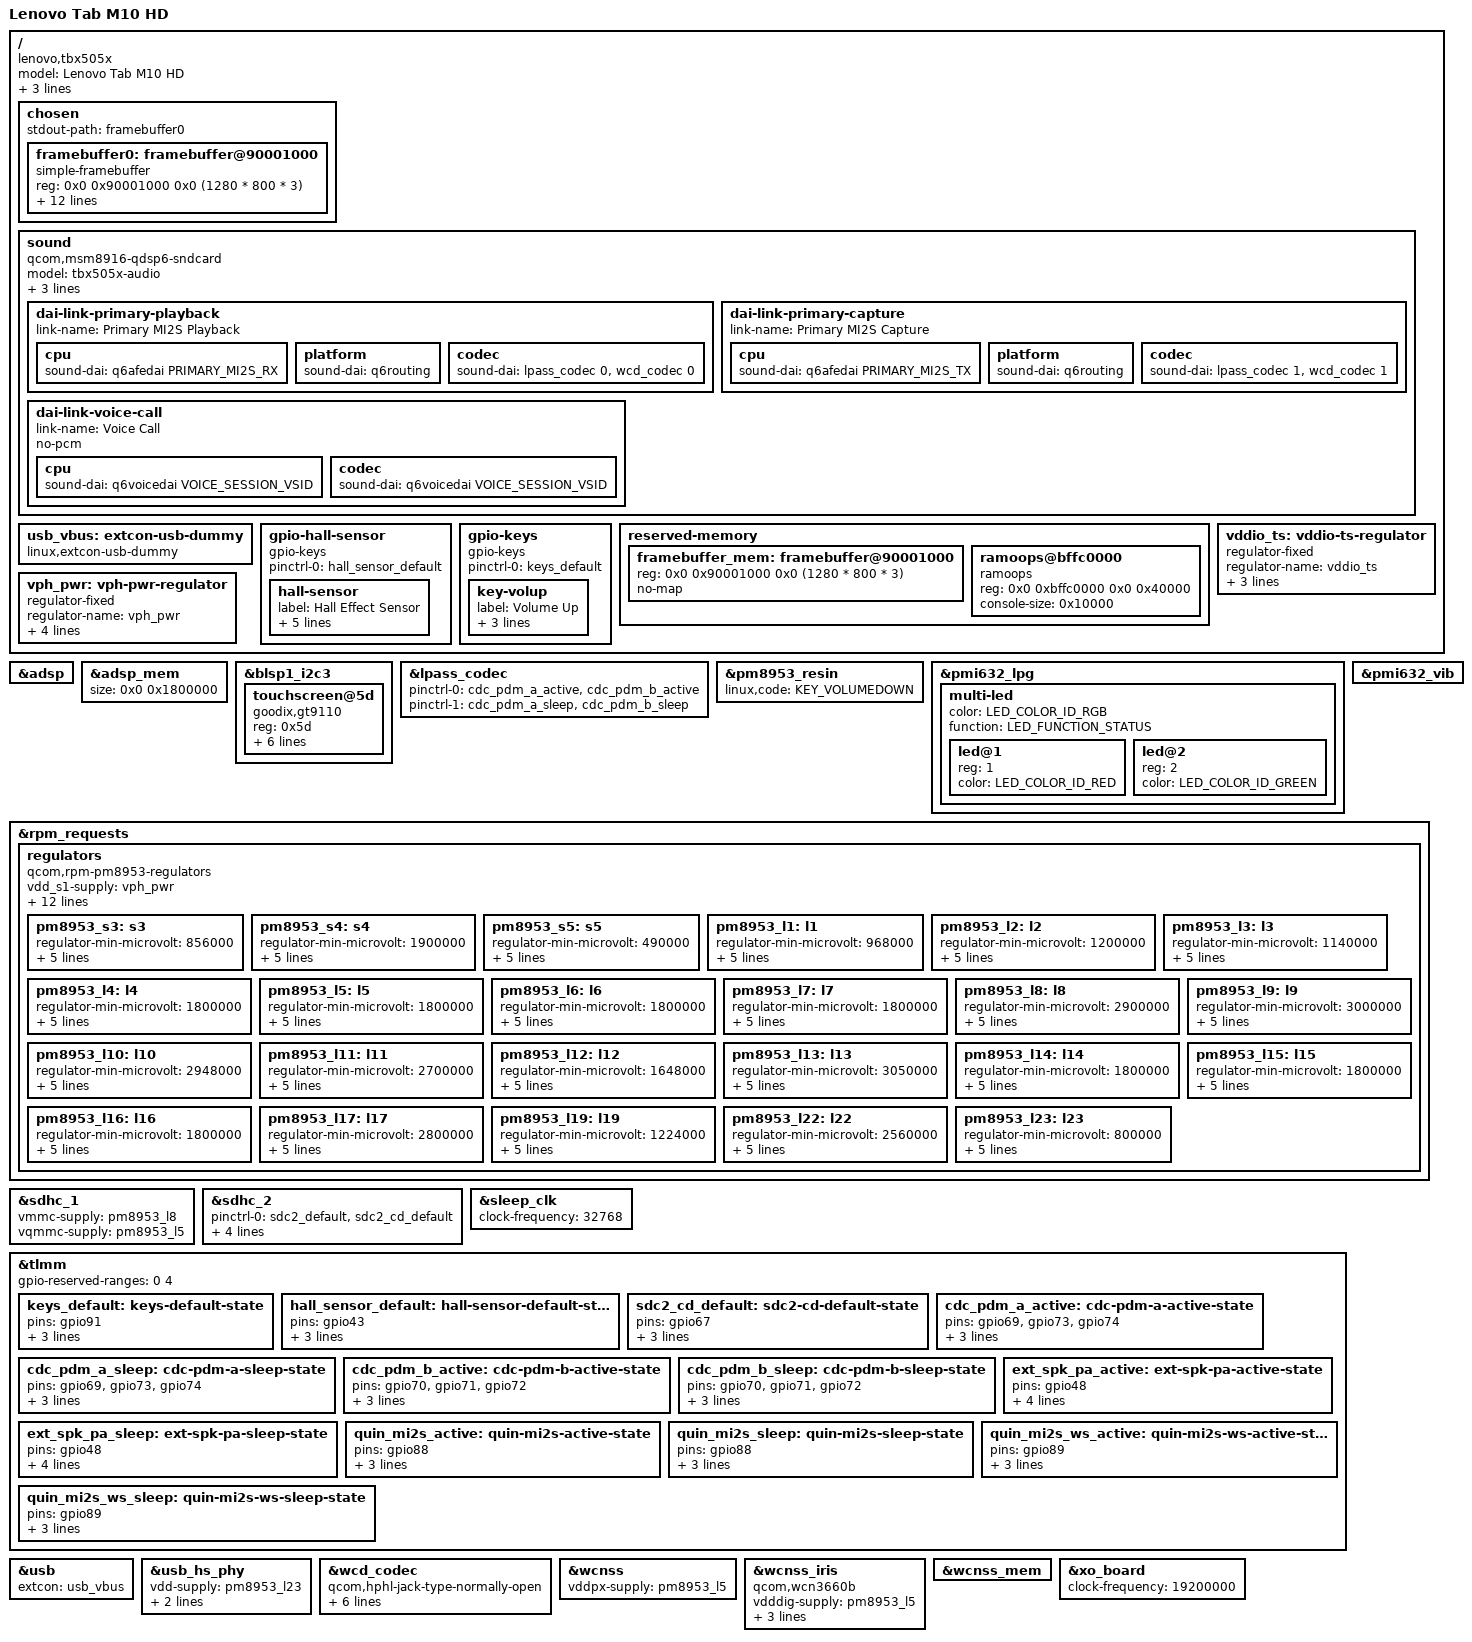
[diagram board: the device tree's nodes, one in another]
// SPDX-License-Identifier: BSD-3-Clause
/*
 * Lenovo Tab M10 HD (TB-X505X) device tree source
 *
 * Copyright (c) 2025 Kaustabh Chakraborty <kauschluss@disroot.org>
 */

/dts-v1/;
#include <dt-bindings/arm/qcom,ids.h>
#include <dt-bindings/gpio/gpio.h>
#include <dt-bindings/leds/common.h>
#include <dt-bindings/sound/qcom,q6afe.h>
#include <dt-bindings/sound/qcom,q6asm.h>
#include "sdm429.dtsi"
#include "pm8953.dtsi"
#include "pmi632.dtsi"

/ {
	model = "Lenovo Tab M10 HD";
	compatible = "lenovo,tbx505x", "qcom,sdm429";
	chassis-type = "tablet";

	qcom,msm-id = <QCOM_ID_SDM429 0>;
	qcom,board-id = <QCOM_BOARD_ID_MTP 2>;

	chosen {
		#address-cells = <2>;
		#size-cells = <2>;
		ranges;

		stdout-path = "framebuffer0";

		framebuffer0: framebuffer@90001000 {
			compatible = "simple-framebuffer";
			reg = <0x0 0x90001000 0x0 (1280 * 800 * 3)>;
			width = <800>;
			height = <1280>;
			stride = <(800 * 3)>;
			format = "r8g8b8";

			clocks = <&gcc GCC_MDSS_AHB_CLK>,
				 <&gcc GCC_MDSS_AXI_CLK>,
				 <&gcc GCC_MDSS_VSYNC_CLK>,
				 <&gcc GCC_MDSS_MDP_CLK>,
				 <&gcc GCC_MDSS_BYTE0_CLK>,
				 <&gcc GCC_MDSS_PCLK0_CLK>,
				 <&gcc GCC_MDSS_ESC0_CLK>;
			power-domains = <&gcc MDSS_GDSC>;
		};
	};

	sound: sound {
		compatible = "qcom,msm8916-qdsp6-sndcard";
		model = "tbx505x-audio";

		/*
		 * Downstream "pri-mi2s-gpios" is actually the PDM bus
		 * (cdc_pdm0, GPIOs 69-74) for the internal WCD codec,
		 * not MI2S. Pinctrl for it lives on &lpass_codec below.
		 *
		 * MIC BIAS External  → Handset Mic → AMIC1
		 * MIC BIAS External2 → Headset Mic → AMIC2 (MBHC)
		 */
		audio-routing =
			"MIC BIAS External",  "Handset Mic",
			"MIC BIAS External2", "Headset Mic",
			"AMIC1", "MIC BIAS External",
			"AMIC2", "MIC BIAS External2";

		/* Internal codec — headphone + speaker playback via PDM */
		dai-link-primary-playback {
			link-name = "Primary MI2S Playback";

			cpu {
				sound-dai = <&q6afedai PRIMARY_MI2S_RX>;
			};

			platform {
				sound-dai = <&q6routing>;
			};

			/*
			 * lpass_codec 0 = LPASS digital interpolator
			 * wcd_codec 0   = PM8953 analog RX (DAC + amp)
			 * Verify labels against your sdm429.dtsi/pm8953.dtsi.
			 */
			codec {
				sound-dai = <&lpass_codec 0>, <&wcd_codec 0>;
			};
		};

		/* Internal codec — handset + headset mic capture via PDM */
		dai-link-primary-capture {
			link-name = "Primary MI2S Capture";

			cpu {
				sound-dai = <&q6afedai PRIMARY_MI2S_TX>;
			};

			platform {
				sound-dai = <&q6routing>;
			};

			codec {
				sound-dai = <&lpass_codec 1>, <&wcd_codec 1>;
			};
		};

		/* Voice call — hostless, routed internally through ADSP */
		dai-link-voice-call {
			link-name = "Voice Call";
			no-pcm;

			cpu {
				sound-dai = <&q6voicedai VOICE_SESSION_VSID>;
			};

			codec {
				sound-dai = <&q6voicedai VOICE_SESSION_VSID>;
			};
		};
	};

	usb_vbus: extcon-usb-dummy {
		compatible = "linux,extcon-usb-dummy";
	};

	gpio-hall-sensor {
		compatible = "gpio-keys";

		pinctrl-0 = <&hall_sensor_default>;
		pinctrl-names = "default";

		hall-sensor {
			label = "Hall Effect Sensor";
			gpios = <&tlmm 41 GPIO_ACTIVE_LOW>;
			linux,input-type = <EV_SW>;
			linux,code = <SW_LID>;
			linux,can-disable;
			wakeup-source;
		};
	};

	gpio-keys {
		compatible = "gpio-keys";

		pinctrl-0 = <&keys_default>;
		pinctrl-names = "default";

		key-volup {
			label = "Volume Up";
			gpios = <&tlmm 91 GPIO_ACTIVE_LOW>;
			debounce-interval = <15>;
			linux,code = <KEY_VOLUMEUP>;
		};
	};

	reserved-memory {
		framebuffer_mem: framebuffer@90001000 {
			reg = <0x0 0x90001000 0x0 (1280 * 800 * 3)>;
			no-map;
		};

		ramoops@bffc0000 {
			compatible = "ramoops";
			reg = <0x0 0xbffc0000 0x0 0x40000>;
			console-size = <0x10000>;
		};
	};

	vddio_ts: vddio-ts-regulator {
		compatible = "regulator-fixed";
		regulator-name = "vddio_ts";
		gpio = <&tlmm 16 GPIO_ACTIVE_HIGH>;
		enable-active-high;
		regulator-boot-on;
	};

	vph_pwr: vph-pwr-regulator {
		compatible = "regulator-fixed";
		regulator-name = "vph_pwr";
		regulator-min-microvolt = <3700000>;
		regulator-max-microvolt = <3700000>;
		regulator-always-on;
		regulator-boot-on;
	};
};

&adsp {
	status = "okay";
};

&adsp_mem {
	size = <0x0 0x1800000>;

	status = "okay";
};

&blsp1_i2c3 {
	status = "okay";

	touchscreen@5d {
		compatible = "goodix,gt9110";
		reg = <0x5d>;
		interrupt-parent = <&tlmm>;
		interrupts = <65 IRQ_TYPE_EDGE_FALLING>;

		VDDIO-supply = <&vddio_ts>;
		reset-gpios = <&tlmm 64 GPIO_ACTIVE_LOW>;

		touchscreen-size-x = <800>;
		touchscreen-size-y = <1280>;
	};
};

/*
 * LPASS internal digital codec — hosts the PDM bus pinctrl.
 * GPIOs 69,73,74 = cdc_pdm0 group A (CLK + DATA)
 * GPIOs 70,71,72 = cdc_pdm0 group B (DATA)
 * Adjust label if sdm429.dtsi exports it as &digital_codec
 * or similar rather than &lpass_codec.
 */
&lpass_codec {
	pinctrl-names = "default", "sleep";
	pinctrl-0 = <&cdc_pdm_a_active &cdc_pdm_b_active>;
	pinctrl-1 = <&cdc_pdm_a_sleep  &cdc_pdm_b_sleep>;
};

&pm8953_resin {
	linux,code = <KEY_VOLUMEDOWN>;

	status = "okay";
};

&pmi632_lpg {
	status = "okay";

	multi-led {
		color = <LED_COLOR_ID_RGB>;
		function = LED_FUNCTION_STATUS;

		#address-cells = <1>;
		#size-cells = <0>;

		led@1 {
			reg = <1>;
			color = <LED_COLOR_ID_RED>;
		};

		led@2 {
			reg = <2>;
			color = <LED_COLOR_ID_GREEN>;
		};
	};
};

&pmi632_vib {
	status = "okay";
};

&rpm_requests {
	regulators {
		compatible = "qcom,rpm-pm8953-regulators";

		vdd_s1-supply = <&vph_pwr>;
		vdd_s2-supply = <&vph_pwr>;
		vdd_s3-supply = <&vph_pwr>;
		vdd_s4-supply = <&vph_pwr>;
		vdd_s5-supply = <&vph_pwr>;
		vdd_s6-supply = <&vph_pwr>;
		vdd_s7-supply = <&vph_pwr>;
		vdd_l1-supply = <&pm8953_s3>;
		vdd_l2_l3-supply = <&pm8953_s3>;
		vdd_l4_l5_l6_l7_l16_l19-supply = <&pm8953_s4>;
		vdd_l8_l11_l12_l13_l14_l15-supply = <&vph_pwr>;
		vdd_l9_l10_l17_l18_l22-supply = <&vph_pwr>;
		vdd_l23-supply = <&pm8953_s3>;

		pm8953_s3: s3 {
			regulator-min-microvolt = <856000>;
			regulator-max-microvolt = <1280000>;
			regulator-enable-ramp-delay = <250>;
			regulator-ramp-delay = <0>;
			regulator-system-load = <100000>;
			regulator-allow-set-load;
		};

		pm8953_s4: s4 {
			regulator-min-microvolt = <1900000>;
			regulator-max-microvolt = <2040000>;
			regulator-enable-ramp-delay = <250>;
			regulator-ramp-delay = <0>;
			regulator-system-load = <100000>;
			regulator-allow-set-load;
		};

		pm8953_s5: s5 {
			regulator-min-microvolt = <490000>;
			regulator-max-microvolt = <980000>;
			regulator-enable-ramp-delay = <250>;
			regulator-ramp-delay = <0>;
			regulator-always-on;
			regulator-boot-on;
		};

		pm8953_l1: l1 {
			regulator-min-microvolt = <968000>;
			regulator-max-microvolt = <1152000>;
			regulator-enable-ramp-delay = <250>;
			regulator-ramp-delay = <0>;
			regulator-system-load = <10000>;
			regulator-allow-set-load;
		};

		pm8953_l2: l2 {
			regulator-min-microvolt = <1200000>;
			regulator-max-microvolt = <1200000>;
			regulator-enable-ramp-delay = <250>;
			regulator-ramp-delay = <0>;
			regulator-system-load = <10000>;
			regulator-allow-set-load;
		};

		pm8953_l3: l3 {
			regulator-min-microvolt = <1140000>;
			regulator-max-microvolt = <1200000>;
			regulator-enable-ramp-delay = <250>;
			regulator-ramp-delay = <0>;
			regulator-system-load = <10000>;
			regulator-allow-set-load;
		};

		pm8953_l4: l4 {
			regulator-min-microvolt = <1800000>;
			regulator-max-microvolt = <1800000>;
			regulator-enable-ramp-delay = <250>;
			regulator-ramp-delay = <0>;
			regulator-system-load = <10000>;
			regulator-allow-set-load;
		};

		pm8953_l5: l5 {
			regulator-min-microvolt = <1800000>;
			regulator-max-microvolt = <1800000>;
			regulator-enable-ramp-delay = <250>;
			regulator-ramp-delay = <0>;
			regulator-system-load = <10000>;
			regulator-allow-set-load;
		};

		pm8953_l6: l6 {
			regulator-min-microvolt = <1800000>;
			regulator-max-microvolt = <1800000>;
			regulator-enable-ramp-delay = <250>;
			regulator-ramp-delay = <0>;
			regulator-system-load = <10000>;
			regulator-allow-set-load;
		};

		pm8953_l7: l7 {
			regulator-min-microvolt = <1800000>;
			regulator-max-microvolt = <1800000>;
			regulator-enable-ramp-delay = <250>;
			regulator-ramp-delay = <0>;
			regulator-system-load = <10000>;
			regulator-allow-set-load;
		};

		pm8953_l8: l8 {
			regulator-min-microvolt = <2900000>;
			regulator-max-microvolt = <2900000>;
			regulator-enable-ramp-delay = <250>;
			regulator-ramp-delay = <0>;
			regulator-system-load = <10000>;
			regulator-allow-set-load;
		};

		pm8953_l9: l9 {
			regulator-min-microvolt = <3000000>;
			regulator-max-microvolt = <3300000>;
			regulator-enable-ramp-delay = <250>;
			regulator-ramp-delay = <0>;
			regulator-system-load = <10000>;
			regulator-allow-set-load;
		};

		pm8953_l10: l10 {
			regulator-min-microvolt = <2948000>;
			regulator-max-microvolt = <3300000>;
			regulator-enable-ramp-delay = <250>;
			regulator-ramp-delay = <0>;
			regulator-system-load = <10000>;
			regulator-allow-set-load;
		};

		pm8953_l11: l11 {
			regulator-min-microvolt = <2700000>;
			regulator-max-microvolt = <3300000>;
			regulator-enable-ramp-delay = <250>;
			regulator-ramp-delay = <0>;
			regulator-system-load = <10000>;
			regulator-allow-set-load;
		};

		pm8953_l12: l12 {
			regulator-min-microvolt = <1648000>;
			regulator-max-microvolt = <3300000>;
			regulator-enable-ramp-delay = <250>;
			regulator-ramp-delay = <0>;
			regulator-system-load = <10000>;
			regulator-allow-set-load;
		};

		pm8953_l13: l13 {
			regulator-min-microvolt = <3050000>;
			regulator-max-microvolt = <3100000>;
			regulator-enable-ramp-delay = <250>;
			regulator-ramp-delay = <0>;
			regulator-system-load = <5000>;
			regulator-allow-set-load;
		};

		pm8953_l14: l14 {
			regulator-min-microvolt = <1800000>;
			regulator-max-microvolt = <3052000>;
			regulator-enable-ramp-delay = <250>;
			regulator-ramp-delay = <0>;
			regulator-system-load = <5000>;
			regulator-allow-set-load;
		};

		pm8953_l15: l15 {
			regulator-min-microvolt = <1800000>;
			regulator-max-microvolt = <3052000>;
			regulator-enable-ramp-delay = <250>;
			regulator-ramp-delay = <0>;
			regulator-system-load = <5000>;
			regulator-allow-set-load;
		};

		pm8953_l16: l16 {
			regulator-min-microvolt = <1800000>;
			regulator-max-microvolt = <1800000>;
			regulator-enable-ramp-delay = <250>;
			regulator-ramp-delay = <0>;
			regulator-system-load = <5000>;
			regulator-allow-set-load;
		};

		pm8953_l17: l17 {
			regulator-min-microvolt = <2800000>;
			regulator-max-microvolt = <2900000>;
			regulator-enable-ramp-delay = <250>;
			regulator-ramp-delay = <0>;
			regulator-system-load = <10000>;
			regulator-allow-set-load;
		};

		pm8953_l19: l19 {
			regulator-min-microvolt = <1224000>;
			regulator-max-microvolt = <1356000>;
			regulator-enable-ramp-delay = <250>;
			regulator-ramp-delay = <0>;
			regulator-system-load = <10000>;
			regulator-allow-set-load;
		};

		pm8953_l22: l22 {
			regulator-min-microvolt = <2560000>;
			regulator-max-microvolt = <3000000>;
			regulator-enable-ramp-delay = <250>;
			regulator-ramp-delay = <0>;
			regulator-system-load = <10000>;
			regulator-allow-set-load;
		};

		pm8953_l23: l23 {
			regulator-min-microvolt = <800000>;
			regulator-max-microvolt = <1000000>;
			regulator-enable-ramp-delay = <250>;
			regulator-ramp-delay = <0>;
			regulator-system-load = <10000>;
			regulator-allow-set-load;
		};
	};
};

&sdhc_1 {
	vmmc-supply = <&pm8953_l8>;
	vqmmc-supply = <&pm8953_l5>;

	status = "okay";
};

&sdhc_2 {
	pinctrl-0 = <&sdc2_default &sdc2_cd_default>;
	pinctrl-1 = <&sdc2_sleep &sdc2_cd_default>;
	pinctrl-names = "default", "sleep";

	vmmc-supply = <&pm8953_l11>;
	vqmmc-supply = <&pm8953_l12>;
	cd-gpios = <&tlmm 67 GPIO_ACTIVE_HIGH>;

	status = "okay";
};

&sleep_clk {
	clock-frequency = <32768>;
};

&tlmm {
	gpio-reserved-ranges = <0 4>;

	keys_default: keys-default-state {
		pins = "gpio91";
		function = "gpio";
		drive-strength = <2>;
		bias-pull-up;
	};

	hall_sensor_default: hall-sensor-default-state {
		pins = "gpio43";
		function = "gpio";
		drive-strength = <6>;
		bias-pull-up;
	};

	sdc2_cd_default: sdc2-cd-default-state {
		pins = "gpio67";
		function = "gpio";
		drive-strength = <2>;
		bias-disable;
	};

	/*
	 * PDM bus for the internal WCD analog codec.
	 * Downstream misleadingly calls this "pri-mi2s-gpios" but the
	 * pin function is cdc_pdm0 — it is PDM, not MI2S.
	 */
	cdc_pdm_a_active: cdc-pdm-a-active-state {
		pins = "gpio69", "gpio73", "gpio74";
		function = "cdc_pdm0";
		drive-strength = <8>;
		bias-disable;
	};

	cdc_pdm_a_sleep: cdc-pdm-a-sleep-state {
		pins = "gpio69", "gpio73", "gpio74";
		function = "cdc_pdm0";
		drive-strength = <2>;
		bias-disable;
	};

	cdc_pdm_b_active: cdc-pdm-b-active-state {
		pins = "gpio70", "gpio71", "gpio72";
		function = "cdc_pdm0";
		drive-strength = <8>;
		bias-disable;
	};

	cdc_pdm_b_sleep: cdc-pdm-b-sleep-state {
		pins = "gpio70", "gpio71", "gpio72";
		function = "cdc_pdm0";
		drive-strength = <2>;
		bias-disable;
	};

	/* External speaker PA enable — confirmed GPIO 48 */
	ext_spk_pa_active: ext-spk-pa-active-state {
		pins = "gpio48";
		function = "gpio";
		drive-strength = <8>;
		bias-disable;
		output-high;
	};

	ext_spk_pa_sleep: ext-spk-pa-sleep-state {
		pins = "gpio48";
		function = "gpio";
		drive-strength = <2>;
		bias-disable;
		output-low;
	};

	/*
	 * Quinary MI2S — downstream "quin-mi2s-gpios" (0xeb).
	 * GPIO 88 = SCK  (confirmed, phandle 0x120)
	 * GPIO 89 = WS   (confirmed by gpio89 grep; decompiler dropped
	 *                 the pins field from phandle 0x121/0x123)
	 */
	quin_mi2s_active: quin-mi2s-active-state {
		pins = "gpio88";
		function = "pri_mi2s";
		drive-strength = <8>;
		bias-disable;
	};

	quin_mi2s_sleep: quin-mi2s-sleep-state {
		pins = "gpio88";
		function = "pri_mi2s";
		drive-strength = <2>;
		bias-pull-down;
	};

	quin_mi2s_ws_active: quin-mi2s-ws-active-state {
		pins = "gpio89";
		function = "pri_mi2s_ws";
		drive-strength = <8>;
		bias-disable;
	};

	quin_mi2s_ws_sleep: quin-mi2s-ws-sleep-state {
		pins = "gpio89";
		function = "pri_mi2s_ws";
		drive-strength = <2>;
		bias-pull-down;
	};
};

&usb {
	extcon = <&usb_vbus>;

	status = "okay";
};

&usb_hs_phy {
	vdd-supply = <&pm8953_l23>;
	vdda1p8-supply = <&pm8953_l7>;
	vdda3p3-supply = <&pm8953_l13>;

	status = "okay";
};

/*
 * WCD analog codec — PM8953 internal (msm8x16_wcd analog half).
 * hphl/gnd normally-open matches downstream qcom,msm-mbhc-hphl/gnd-swh = 1.
 * micbias1/2-ext-cap from downstream qcom,msm-micbias1/2-ext-cap flags.
 * spkr-pa-gpios drives GPIO 48 to enable the external speaker amplifier.
 * Adjust label to match pm8953.dtsi (may be &pm8953_codec or &wcd_codec).
 */
&wcd_codec {
	qcom,hphl-jack-type-normally-open;
	qcom,gnd-jack-type-normally-open;
	qcom,micbias1-ext-cap;
	qcom,micbias2-ext-cap;
	qcom,mbhc-vthreshold-low = <75 150 237 450 500>;
	qcom,mbhc-vthreshold-high = <75 150 237 450 500>;

	spkr-pa-gpios = <&tlmm 48 GPIO_ACTIVE_HIGH>;
};

&wcnss {
	vddpx-supply = <&pm8953_l5>;

	status = "okay";
};

&wcnss_iris {
	compatible = "qcom,wcn3660b";

	vdddig-supply = <&pm8953_l5>;
	vddpa-supply = <&pm8953_l9>;
	vddrfa-supply = <&pm8953_l19>;
	vddxo-supply = <&pm8953_l7>;
};

&wcnss_mem {
	status = "okay";
};

&xo_board {
	clock-frequency = <19200000>;
};
